# AE612FA0E5597LS0_CM55_HP_View register map
Vendor: Alif Semiconductor; Series: E6; File version: 1.0
CPU: CM55 r1p0, selectable endian, MPU, FPU, double-precision FPU, DSP, VTOR, 8 interrupt priority bits, 1 SAU regions
Registers are 32-bit, read-write, reset 0x0 unless marked. A register's access mark holds for its fields unless they carry their own. Offsets are from the block's base; [hi:lo] are bit positions; lines under a group give offsets from that group; {n}, {i} and the like mark numbered series.

## DAC120
Base 0x49028000
Same registers: DAC121 0x49029000
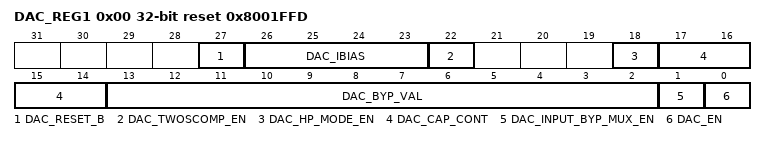
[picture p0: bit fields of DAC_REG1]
0x00 DAC_REG1 reset 0x8001FFD (reset mask 0xF8783FFF) — REG1 DAC Control Register
  [27] DAC_RESET_B — DAC reset:
    0=Reset asserted; 1=Reset released
  [26:23] DAC_IBIAS — Trims buffer output current (HP mode): From 0000 = 0 uA to 1111 = 1.5 mA Default is 1111 for DAC120 and 0000 for DAC121 Step size ~100 uA
  [22] DAC_TWOSCOMP_EN — Converts two's complement to unsigned binary data:
    0=Input data is unsigned; 1=Input data is two's complement signed (conversion to unsigned enable)
  [18] DAC_HP_MODE_EN — DAC high-performance mode enable.
    0=Low-power (LP) mode (default for DAC121); 1=High-performance (HP) mode (default for DAC120)
  [17:14] DAC_CAP_CONT — Trims HP mode capacitance compensation: From xx00 = 2 pF to xx11 = 8 pF Step size = 2 pF Default is xx11 = 8 pF for DAC120 and xx00 for DAC121 Bits [17-16] = Don't care
  [13:2] DAC_BYP_VAL — DAC input data in bypass mode
  [1] DAC_INPUT_BYP_MUX_EN — Selects DAC input data source:
    0=DAC_IN register; 1=DAC_REG1[DAC_BYP_VAL] bitfield (bypass mode)
  [0] DAC_EN — DAC enable:
    0=DAC is disabled; 1=DAC is enabled
0x04 DAC_IN — DAC Input Value Register
  [11:0] VALUE — Value used by DAC analog portion for conversion.

## DAC6
Base 0x4902A000
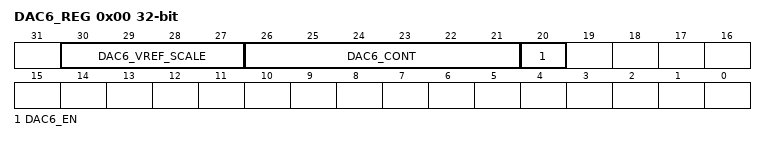
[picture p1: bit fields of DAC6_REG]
0x00 DAC6_REG — DAC6 Register
  [30:27] DAC6_VREF_SCALE — Allows you to scale the input reference to the DAC6. Step Size = 1/16
    0=1x; 15=2x
  [26:21] DAC6_CONT — This is the output of DAC6 programmable reference voltage. DAC6 Output = (DAC6_VREF_SCALE x DAC6_CONT) / 64
  [20] DAC6_EN — DAC6 Enable. DAC6 takes an input reference and generates a 6-bit programmable output voltage reference.

## ADC_VREF
Base 0x4902B000
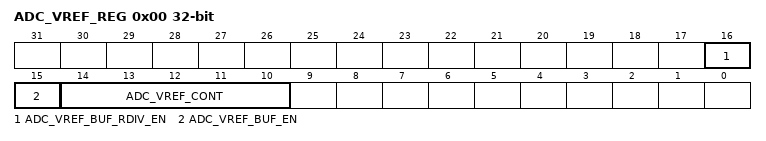
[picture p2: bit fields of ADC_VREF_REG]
0x00 ADC_VREF_REG — ADC_VREF Register
  [16] ADC_VREF_BUF_RDIV_EN — ADC Vref divider enable
    0=Vref = 1.8 V; 1=Vref = 1.5 V
  [15] ADC_VREF_BUF_EN — ADC Vref buffer enable. Turn off if external VREF is connected.
    0=ADC Vref is off; 1=ADC Vref is on
  [14:10] ADC_VREF_CONT — Control for ADC Vref (desired 1.8 V): 1.8 V +- 100 mV, where: Step size = 7 mV
    0=Val_0b00000 (-100 mV); 31=Val_0b11111 (100 mV); 16=Val_0b10000 (1.8 V = Default (0x10))

## HWSEM0
Base 0x4902E000
Same registers: HWSEM{n} {0x4902E000+0x10*n} (n=1..15)
0x00 HWSEM_REQ_REG reset not defined — Request register
  [31:0] REQ_ACQ — Request a HWSEM module by writing the processor ID into this field. Check the status of the HWSEM request by reading this field.
0x04 HWSEM_REL_REG reset not defined — Release register
  [31:0] REL_CHK — Release the HWSEM by writing the processor ID into this field. Check the current HWSEM count by reading this field.
0x08 HWSEM_RST_REG wo reset not defined — Reset register
  [31:0] RST — Reset the semaphore count and current master ID.

## EVTRTR0
Base 0x49035000
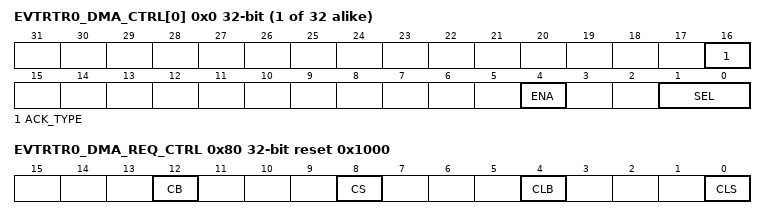
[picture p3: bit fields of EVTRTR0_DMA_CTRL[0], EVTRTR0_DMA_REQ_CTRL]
{0x0+4i} EVTRTR0_DMA_CTRL[{i}] (i=0..31) — DMA/Event Router Control and Status Register (n)
  [16] ACK_TYPE ro — DMA handshake type status for DMA peripheral
    0=Peripheral completes the REQ-ACK handshake with DMA controller. Event Router passing through REQ-ACK between DMA controller and peripheral.; 1=Event Router completes the REQ-ACK handshake with DMA controller. Peripheral raises DMA request without responding to ACK from DMA controller.
  [4] ENA — DMA channel enable
    0=Disable DMA channel; 1=Enable DMA channel
  [1:0] SEL — Select one channel from the four input groups
    {v}=Select group {v} (v=0..3)
0x80 EVTRTR0_DMA_REQ_CTRL reset 0x1000 — DMA Request Control Register
  [all] fields
    0=Disable; 1=Enable
  [12] CB — Enable DMA request on DMACBREQ (DMAC Burst Request) Note: It is recommended to enable all DMA requests on the burst request line (DMACBREQ). For single transfer, the number of beats in a burst should be set to 1 (DMA_CCRn[SRC_BURST_LEN] = 0x0).
  [8] CS — Enable DMA request on DMACSREQ (DMAC Single Request) Note: It is recommended to enable all DMA requests on the burst request line (DMACBREQ), even for single transfer.
  [4] CLB — Enable DMA request on DMACLBREQ (DMAC Last Burst Request) Note: Do not use. The current implementation does not support transfers from a peripheral with an unspecified length ('peripheral length management').
  [0] CLS — Enable DMA request on DMACLSREQ (DMAC Last Single Request) Note: Do not use. The current implementation does not support transfers from a peripheral with an unspecified length ('peripheral length management').
0x90 EVTRTR0_DMA_ACK_TYPE0 reset 0xFFFFFF00 — DMA Handshake Type Register 0
  [31:0] ACK — Select DMA handshake type for DMA group #0
0x94 EVTRTR0_DMA_ACK_TYPE1 reset 0xFF3FF300 — DMA Handshake Type Register 1
  [31:0] ACK — Select DMA handshake type for DMA group #1
0x98 EVTRTR0_DMA_ACK_TYPE2 reset 0xC3FF0000 — DMA Handshake Type Register 2
  [31:0] ACK — Select DMA handshake type for DMA group #2
0x9C EVTRTR0_DMA_ACK_TYPE3 — DMA Handshake Type Register 3
  [31:0] ACK — Select DMA handshake type for DMA group #3

## CANFD0_CNT
Base 0x49037000
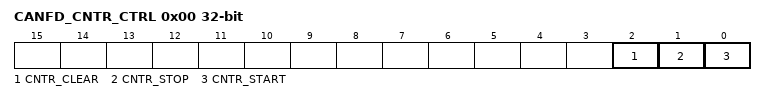
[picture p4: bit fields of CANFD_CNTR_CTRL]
0x00 CANFD_CNTR_CTRL wo — CANFD Counter Control Register
  [2] CNTR_CLEAR — Clear the CANFD counter.
  [1] CNTR_STOP — Stop the CANFD counter.
  [0] CNTR_START — Start the CANFD counter.
0x04 CANFD_CNTR_LOW — CANFD Counter Low Register
  [31:0] CNTR_LO — CANFD counter bits [31:0].
0x08 CANFD_CNTR_HIGH — CANFD Counter High Register
  [31:0] CNTR_HI — CANFD counter bits [63:32].

## M55HP_NVIC_S
Base 0xE000E100
Same registers: M55HP_NVIC_NS 0xE002E100
{0x0+4i} NVIC_ISER[{i}] (i=0..14) — Interrupt Set-Enable Register (n)
  [31:0] SETENA — Allows to enable an interrupt or read the status. For each bit: Read 0x0: Interrupt is disabled Read 0x1: Interrupt is enabled Write 0x0: No effect Write 0x1: Enable interrupt
{0x80+4i} NVIC_ICER[{i}] (i=0..14) — Interrupt Clear-Enable Register (n)
  [31:0] CLRENA — Allows to disable an interrupt or read the status. For each bit: Read 0x0: Interrupt is disabled Read 0x1: Interrupt is enabled Write 0x0: No effect Write 0x1: Disable interrupt
{0x100+4i} NVIC_ISPR[{i}] (i=0..14) — Interrupt Set-Pending Register (n)
  [31:0] SETPEND — Allows to set an interrupt to pending state or read the status. For each bit: Read 0x0: Interrupt is not pending Read 0x1: Interrupt is pending Write 0x0: No effect Write 0x1: Set interrupt to pending state
{0x180+4i} NVIC_ICPR[{i}] (i=0..14) — Interrupt Clear-Pending Register (n)
  [31:0] CLRPEND — Allows to clear an interrupt to not pending state or read the status. For each bit: Read 0x0: Interrupt is not pending Read 0x1: Interrupt is pending Write 0x0: No effect Write 0x1: Clear pending state of interrupt
{0x200+4i} NVIC_IABR[{i}] (i=0..14) ro — Interrupt Active Bit Register (n)
  [31:0] ACTIVE — Indicates the active state of an interrupt. For each bit:
    0=Interrupt is not active; 1=Interrupt is active
{0x280+4i} NVIC_ITNS[{i}] (i=0..14) — Interrupt Target Non-Secure Register (n)
  [31:0] ITNS — Determines whether an interrupt targets non-secure or secure state. For each bit:
    0=Interrupt targets secure state; 1=Interrupt targets non-secure state
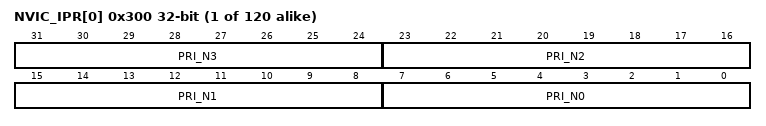
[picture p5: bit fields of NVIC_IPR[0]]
{0x300+4i} NVIC_IPR[{i}] (i=0..119) — Interrupt Priority Register (n)
  [31:24] PRI_N3 — Allows to set or read the priority level for interrupt 3
  [23:16] PRI_N2 — Allows to set or read the priority level for interrupt 2
  [15:8] PRI_N1 — Allows to set or read the priority level for interrupt 1
  [7:0] PRI_N0 — Allows to set or read the priority level for interrupt 0
    0=Priority level is 0 (highest); 1=Priority level is 1; 255=Priority level is 255 (lowest)
